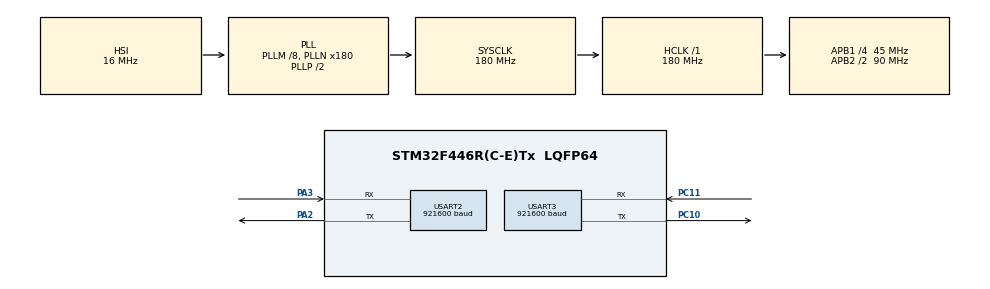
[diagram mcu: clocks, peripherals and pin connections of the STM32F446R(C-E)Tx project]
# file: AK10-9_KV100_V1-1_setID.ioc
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Mcu.Family=STM32F4
Mcu.Name=STM32F446R(C-E)Tx
Mcu.Package=LQFP64
NVIC.PriorityGroup=NVIC_PRIORITYGROUP_4
PA2.Mode=Asynchronous
PA2.Signal=USART2_TX
PA3.Mode=Asynchronous
PA3.Signal=USART2_RX
PC10.Mode=Asynchronous
PC10.Signal=USART3_TX
PC11.Mode=Asynchronous
PC11.Signal=USART3_RX
ProjectManager.HeapSize=0x200
ProjectManager.StackSize=0x400
ProjectManager.TargetToolchain=STM32CubeIDE
RCC.AHBFreq_Value=180000000
RCC.APB1CLKDivider=RCC_HCLK_DIV4
RCC.APB1Freq_Value=45000000
RCC.APB1TimFreq_Value=90000000
RCC.APB2CLKDivider=RCC_HCLK_DIV2
RCC.APB2Freq_Value=90000000
RCC.APB2TimFreq_Value=180000000
RCC.CortexFreq_Value=180000000
RCC.HCLKFreq_Value=180000000
RCC.PLLM=8
RCC.PLLN=180
RCC.SYSCLKFreq_VALUE=180000000
RCC.SYSCLKSource=RCC_SYSCLKSOURCE_PLLCLK
RCC.USBFreq_Value=180000000
RCC.VCOOutputFreq_Value=360000000
USART2.BaudRate=921600
USART2.VirtualMode=VM_ASYNC
USART3.BaudRate=921600
USART3.VirtualMode=VM_ASYNC
board=custom

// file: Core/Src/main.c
/* USER CODE BEGIN Header */
/**
  ******************************************************************************
  * @file           : main.c
  * @brief          : Main program body
  ******************************************************************************
  * @attention
  *
  * Copyright (c) 2026 STMicroelectronics.
  * All rights reserved.
  *
  * This software is licensed under terms that can be found in the LICENSE file
  * in the root directory of this software component.
  * If no LICENSE file comes with this software, it is provided AS-IS.
  *
  ******************************************************************************
  */
/* USER CODE END Header */
#include "main.h"

UART_HandleTypeDef huart2;
UART_HandleTypeDef huart3;

void SystemClock_Config(void);
static void MX_GPIO_Init(void);
static void MX_USART2_UART_Init(void);
static void MX_USART3_UART_Init(void);

int main(void)
{

  /* MCU Configuration--------------------------------------------------------*/

  /* Reset of all peripherals, Initializes the Flash interface and the Systick. */
  HAL_Init();

  /* Configure the system clock */
  SystemClock_Config();

  /* Initialize all configured peripherals */
  MX_GPIO_Init();
  MX_USART2_UART_Init();
  MX_USART3_UART_Init();
  /* USER CODE BEGIN 2 */
  __HAL_UART_CLEAR_OREFLAG(&huart2);
  __HAL_UART_CLEAR_OREFLAG(&huart3);

  /* USER CODE END 2 */

  /* Infinite loop */
  while (1)
  {

    /* USER CODE BEGIN 3 */
	  // 1. 從電腦收資料，光速丟給馬達
	        if (__HAL_UART_GET_FLAG(&huart2, UART_FLAG_RXNE) != RESET) {
	            uint8_t data = huart2.Instance->DR;          // 直接從底層硬體抓字元
	            huart3.Instance->DR = data;                  // 直接塞進馬達的發送通道
	            while(__HAL_UART_GET_FLAG(&huart3, UART_FLAG_TC) == RESET); // 等待發送完成
	        }

	        // 2. 從馬達收資料，光速丟回電腦螢幕
	        if (__HAL_UART_GET_FLAG(&huart3, UART_FLAG_RXNE) != RESET) {
	            uint8_t data = huart3.Instance->DR;          // 直接從底層硬體抓字元
	            huart2.Instance->DR = data;                  // 直接塞進電腦螢幕的發送通道
	            while(__HAL_UART_GET_FLAG(&huart2, UART_FLAG_TC) == RESET); // 等待發送完成
	        }
	    }
  /* USER CODE END 3 */
}

void SystemClock_Config(void)
{
  RCC_OscInitTypeDef RCC_OscInitStruct = {0};
  RCC_ClkInitTypeDef RCC_ClkInitStruct = {0};

  /** Configure the main internal regulator output voltage
  */
  __HAL_RCC_PWR_CLK_ENABLE();
  __HAL_PWR_VOLTAGESCALING_CONFIG(PWR_REGULATOR_VOLTAGE_SCALE1);

  /** Initializes the RCC Oscillators according to the specified parameters
  * in the RCC_OscInitTypeDef structure.
  */
  RCC_OscInitStruct.OscillatorType = RCC_OSCILLATORTYPE_HSI;
  RCC_OscInitStruct.HSIState = RCC_HSI_ON;
  RCC_OscInitStruct.HSICalibrationValue = RCC_HSICALIBRATION_DEFAULT;
  RCC_OscInitStruct.PLL.PLLState = RCC_PLL_ON;
  RCC_OscInitStruct.PLL.PLLSource = RCC_PLLSOURCE_HSI;
  RCC_OscInitStruct.PLL.PLLM = 8;
  RCC_OscInitStruct.PLL.PLLN = 180;
  RCC_OscInitStruct.PLL.PLLP = RCC_PLLP_DIV2;
  RCC_OscInitStruct.PLL.PLLQ = 2;
  RCC_OscInitStruct.PLL.PLLR = 2;
  if (HAL_RCC_OscConfig(&RCC_OscInitStruct) != HAL_OK)
  {
    Error_Handler();
  }

  /** Activate the Over-Drive mode
  */
  if (HAL_PWREx_EnableOverDrive() != HAL_OK)
  {
    Error_Handler();
  }

  /** Initializes the CPU, AHB and APB buses clocks
  */
  RCC_ClkInitStruct.ClockType = RCC_CLOCKTYPE_HCLK|RCC_CLOCKTYPE_SYSCLK
                              |RCC_CLOCKTYPE_PCLK1|RCC_CLOCKTYPE_PCLK2;
  RCC_ClkInitStruct.SYSCLKSource = RCC_SYSCLKSOURCE_PLLCLK;
  RCC_ClkInitStruct.AHBCLKDivider = RCC_SYSCLK_DIV1;
  RCC_ClkInitStruct.APB1CLKDivider = RCC_HCLK_DIV4;
  RCC_ClkInitStruct.APB2CLKDivider = RCC_HCLK_DIV2;

  if (HAL_RCC_ClockConfig(&RCC_ClkInitStruct, FLASH_LATENCY_5) != HAL_OK)
  {
    Error_Handler();
  }
}

static void MX_USART2_UART_Init(void)
{

  huart2.Instance = USART2;
  huart2.Init.BaudRate = 921600;
  huart2.Init.WordLength = UART_WORDLENGTH_8B;
  huart2.Init.StopBits = UART_STOPBITS_1;
  huart2.Init.Parity = UART_PARITY_NONE;
  huart2.Init.Mode = UART_MODE_TX_RX;
  huart2.Init.HwFlowCtl = UART_HWCONTROL_NONE;
  huart2.Init.OverSampling = UART_OVERSAMPLING_16;
  if (HAL_UART_Init(&huart2) != HAL_OK)
  {
    Error_Handler();
  }

}

static void MX_USART3_UART_Init(void)
{

  huart3.Instance = USART3;
  huart3.Init.BaudRate = 921600;
  huart3.Init.WordLength = UART_WORDLENGTH_8B;
  huart3.Init.StopBits = UART_STOPBITS_1;
  huart3.Init.Parity = UART_PARITY_NONE;
  huart3.Init.Mode = UART_MODE_TX_RX;
  huart3.Init.HwFlowCtl = UART_HWCONTROL_NONE;
  huart3.Init.OverSampling = UART_OVERSAMPLING_16;
  if (HAL_UART_Init(&huart3) != HAL_OK)
  {
    Error_Handler();
  }

}

static void MX_GPIO_Init(void)
{

  /* GPIO Ports Clock Enable */
  __HAL_RCC_GPIOA_CLK_ENABLE();
  __HAL_RCC_GPIOC_CLK_ENABLE();

}

void Error_Handler(void)
{
  __disable_irq();
  while (1)
  {
  }
}
